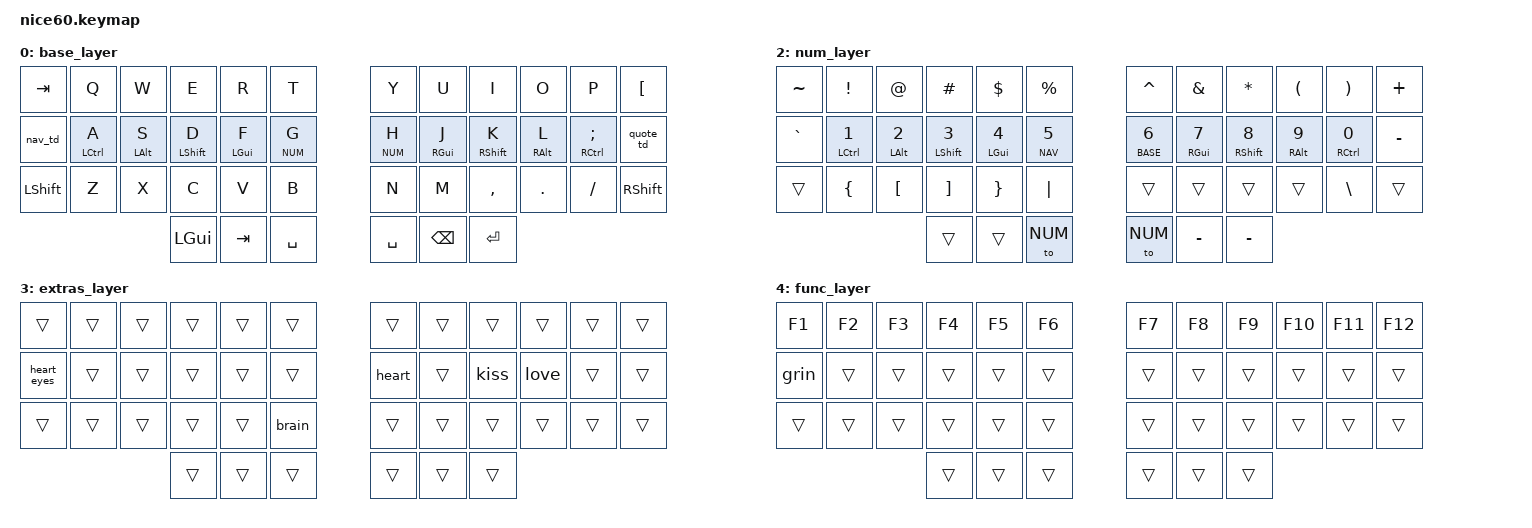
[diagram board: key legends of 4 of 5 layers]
/*
 * Copyright (c) 2020 The ZMK Contributors
 *
 * SPDX-License-Identifier: MIT
 */

#include <behaviors.dtsi>
#include <dt-bindings/zmk/keys.h>
#include <dt-bindings/zmk/bt.h>

// Layer definitions
#define BASE 0
#define NAV 1
#define NUM 2
#define EXTRAS 3
#define FUNC 4

// Timing configurations
#define QUICK_TAP_MS 175
#define TAP_TERM_MS 150
#define HOLD_TERM_MS 250

/ {
    behaviors {
        // Home row modifiers with different timing
        hml: homerow_mods_left {
            compatible = "zmk,behavior-hold-tap";
            label = "HOMEROW_MODS_LEFT";
            #binding-cells = <2>;
            bindings = <&kp>, <&kp>;
            flavor = "balanced";
            tapping-term-ms = <HOLD_TERM_MS>;
            quick-tap-ms = <QUICK_TAP_MS>;
            require-prior-idle-ms = <150>;
            hold-trigger-key-positions = <6 7 8 9 10 11 18 19 20 21 22 23 30 31 32 33 34 35>;
            hold-trigger-on-release;
        };

        hmr: homerow_mods_right {
            compatible = "zmk,behavior-hold-tap";
            label = "HOMEROW_MODS_RIGHT";
            #binding-cells = <2>;
            bindings = <&kp>, <&kp>;
            flavor = "balanced";
            tapping-term-ms = <HOLD_TERM_MS>;
            quick-tap-ms = <QUICK_TAP_MS>;
            require-prior-idle-ms = <150>;
            hold-trigger-key-positions = <0 1 2 3 4 5 12 13 14 15 16 17 24 25 26 27 28 29>;
            hold-trigger-on-release;
        };

        // Layer tap behavior
        ltq: layer_tap_quick {
            compatible = "zmk,behavior-hold-tap";
            label = "LAYER_TAP_QUICK";
            #binding-cells = <2>;
            bindings = <&mo>, <&kp>;
            flavor = "balanced";
            tapping-term-ms = <TAP_TERM_MS>;
            quick-tap-ms = <QUICK_TAP_MS>;
        };

        // Tap dance for navigation layer toggle
        nav_td: nav_tap_dance {
            compatible = "zmk,behavior-tap-dance";
            label = "NAV_TAP_DANCE";
            #binding-cells = <0>;
            bindings = <&ltq NAV CAPS>, <&tog NAV>;
            tapping-term-ms = <150>;
        };

        // Tap dance for quote/navigation
        quote_td: quote_tap_dance {
            compatible = "zmk,behavior-tap-dance";
            label = "QUOTE_TAP_DANCE";
            #binding-cells = <0>;
            bindings = <&ltq NAV SQT>, <&tog NAV>;
            tapping-term-ms = <150>;
        };

        // Modifier with layer access
        mod_nav: modifier_navigation {
            compatible = "zmk,behavior-hold-tap";
            label = "MODIFIER_NAVIGATION";
            #binding-cells = <2>;
            bindings = <&mo>, <&sk>;
            flavor = "balanced";
            tapping-term-ms = <HOLD_TERM_MS>;
            quick-tap-ms = <QUICK_TAP_MS>;
        };

        grin: grin_emoji {
            compatible = "zmk,behavior-unicode";
            label = "GRIN_EMOJI";
            #binding-cells = <0>;
            unicode = <0x1F600>;
        };
        heart_eyes: heart_eyes_emoji {
            compatible = "zmk,behavior-unicode";
            label = "HEART_EYES_EMOJI";
            #binding-cells = <0>;
            unicode = <0x1F60D>;
        };
        heart: heart_emoji {
            compatible = "zmk,behavior-unicode";
            label = "HEART_EMOJI";
            #binding-cells = <0>;
            unicode = <0x2764>;
        };
        kiss: kiss_emoji {
            compatible = "zmk,behavior-unicode";
            label = "KISS_EMOJI";
            #binding-cells = <0>;
            unicode = <0x1F618>;
        };
        love: love_emoji {
            compatible = "zmk,behavior-unicode";
            label = "LOVE_EMOJI";
            #binding-cells = <0>;
            unicode = <0x1F970>;
        };
        brain: brain_emoji {
            compatible = "zmk,behavior-unicode";
            label = "BRAIN_EMOJI";
            #binding-cells = <0>;
            unicode = <0x1F9E0>;
        };
    };

    combos {
        compatible = "zmk,combos";
        
        // Escape combo (Tab + Q)
        combo_esc {
            timeout-ms = <50>;
            key-positions = <0 1>;
            bindings = <&kp ESC>;
        };

        // Layer switch combo (Alt keys)
        combo_base {
            timeout-ms = <50>;
            key-positions = <37 38>; // Left and right alt thumb positions
            bindings = <&to BASE>;
        };

        // Workspace navigation combos
        combo_ws0 {
            timeout-ms = <50>;
            key-positions = <7 8>; // U + I
            bindings = <&kp LG(N0)>;
        };

        combo_ws_prev {
            timeout-ms = <50>;
            key-positions = <8 9>; // I + O
            bindings = <&kp LG(MINUS)>;
        };

        combo_ws_next {
            timeout-ms = <50>;
            key-positions = <9 10>; // O + P
            bindings = <&kp LG(EQUAL)>;
        };

        // Print screen combo
        combo_print {
            timeout-ms = <50>;
            key-positions = <24 25>; // Z + X
            bindings = <&kp PSCRN>;
        };
    };

    keymap {
        compatible = "zmk,keymap";

        // BASE layer (0)
        base_layer {
            bindings = <
                &kp TAB    &kp Q      &kp W      &kp E       &kp R       &kp T           &kp Y       &kp U       &kp I       &kp O       &kp P       &kp LBKT
                &nav_td    &hml LCTRL A &hml LALT S &hml LSHFT D &hml LGUI F &ltq NUM G     &ltq NUM H  &hmr RGUI J &hmr RSHFT K &hmr RALT L &hmr RCTRL SEMI &quote_td
                &kp LSHFT  &kp Z      &kp X      &kp C       &kp V       &kp B           &kp N       &kp M       &kp COMMA   &kp DOT     &kp FSLH    &kp RSHFT
                                                 &kp LGUI    &kp TAB     &kp SPACE       &kp SPACE   &kp BSPC    &kp RET
            >;
        };

        // NAVIGATION layer (1)
        nav_layer {
            bindings = <
                &kp HOME   &kp PG_UP  &kp INS    &kp UP      &kp DEL     &trans
                &to BASE   &hml LCTRL &kp PG_DN &hml LALT &kp LEFT &hml LSHFT &kp DOWN &hml LGUI &kp RIGHT &trans
                &trans     &grin &trans &trans      &trans      &trans
                                                 &trans      &trans      &to BASE        &to BASE    &trans      &trans
            >;
        };

        // NUMERIC layer (2)
        num_layer {
            bindings = <
                &kp TILDE  &kp EXCL   &kp AT     &kp HASH    &kp DLLR    &kp PRCNT       &kp CARET   &kp AMPS    &kp STAR    &kp LPAR    &kp RPAR    &kp PLUS
                &kp GRAVE  &hml LCTRL N1 &hml LALT N2 &hml LSHFT N3 &hml LGUI N4 &ltq NAV N5   &ltq BASE N6 &hmr RGUI N7 &hmr RSHFT N8 &hmr RALT N9 &hmr RCTRL N0 &kp MINUS
                &trans     &kp LBRC   &kp LBKT   &kp RBKT    &kp RBRC    &kp PIPE        &trans      &trans      &trans      &trans      &kp BSLH    &trans
                                                 &trans      &trans      &to NUM         &to NUM     &kp MINUS   &kp MINUS
            >;
        };

        // EXTRAS layer (3) - Emojis and special characters
        extras_layer {
            bindings = <
                &trans     &trans     &trans     &trans      &trans      &trans          &trans      &trans      &trans      &trans      &trans      &trans
                &heart_eyes &trans &trans &trans      &trans      &trans          &heart &trans &kiss &love &trans      &trans
                &trans     &trans     &trans     &trans      &trans      &brain &trans      &trans      &trans      &trans      &trans      &trans
                                                 &trans      &trans      &trans          &trans      &trans      &trans
            >;
        };

        // FUNCTION layer (4)
        func_layer {
            bindings = <
                &kp F1     &kp F2     &kp F3     &kp F4      &kp F5      &kp F6          &kp F7      &kp F8      &kp F9      &kp F10     &kp F11     &kp F12
                &grin &trans  &trans     &trans      &trans      &trans          &trans      &trans      &trans      &trans      &trans      &trans
                &trans     &trans     &trans     &trans      &trans      &trans          &trans      &trans      &trans      &trans      &trans      &trans
                                                 &trans      &trans      &trans          &trans      &trans      &trans
            >;
        };
    };
};
